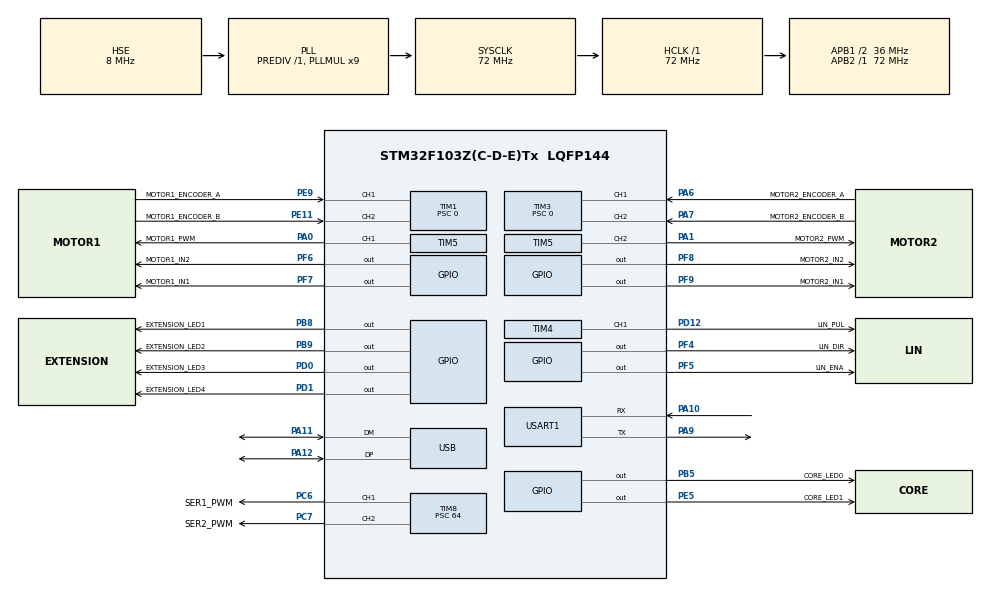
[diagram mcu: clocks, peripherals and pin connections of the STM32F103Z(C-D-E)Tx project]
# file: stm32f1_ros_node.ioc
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Dma.Request0=USART1_RX
Dma.Request1=USART1_TX
Dma.USART1_RX.0.Direction=DMA_PERIPH_TO_MEMORY
Dma.USART1_RX.0.Instance=DMA1_Channel5
Dma.USART1_RX.0.MemDataAlignment=DMA_MDATAALIGN_BYTE
Dma.USART1_RX.0.MemInc=DMA_MINC_ENABLE
Dma.USART1_RX.0.Mode=DMA_CIRCULAR
Dma.USART1_RX.0.PeriphDataAlignment=DMA_PDATAALIGN_BYTE
Dma.USART1_RX.0.PeriphInc=DMA_PINC_DISABLE
Dma.USART1_RX.0.Priority=DMA_PRIORITY_HIGH
Dma.USART1_TX.1.Direction=DMA_MEMORY_TO_PERIPH
Dma.USART1_TX.1.Instance=DMA1_Channel4
Dma.USART1_TX.1.MemDataAlignment=DMA_MDATAALIGN_BYTE
Dma.USART1_TX.1.MemInc=DMA_MINC_ENABLE
Dma.USART1_TX.1.Mode=DMA_NORMAL
Dma.USART1_TX.1.PeriphDataAlignment=DMA_PDATAALIGN_BYTE
Dma.USART1_TX.1.PeriphInc=DMA_PINC_DISABLE
Dma.USART1_TX.1.Priority=DMA_PRIORITY_HIGH
IWDG.Prescaler=IWDG_PRESCALER_128
Mcu.Family=STM32F1
Mcu.Name=STM32F103Z(C-D-E)Tx
Mcu.Package=LQFP144
NVIC.DMA1_Channel4_IRQn=true\:0\:0\:false\:false\:true\:false\:true
NVIC.DMA1_Channel5_IRQn=true\:0\:0\:false\:false\:true\:false\:true
NVIC.PriorityGroup=NVIC_PRIORITYGROUP_4
NVIC.USART1_IRQn=true\:0\:0\:false\:false\:true\:true\:true
NVIC.USB_LP_CAN1_RX0_IRQn=true\:0\:0\:false\:false\:true\:false\:true
OSC_IN.Mode=HSE-External-Oscillator
OSC_IN.Signal=RCC_OSC_IN
OSC_OUT.Mode=HSE-External-Oscillator
OSC_OUT.Signal=RCC_OSC_OUT
PA0-WKUP.GPIO_Label=MOTOR1_PWM
PA0-WKUP.Signal=S_TIM5_CH1
PA1.GPIO_Label=MOTOR2_PWM
PA1.Signal=S_TIM5_CH2
PA10.Mode=Asynchronous
PA10.Signal=USART1_RX
PA11.Mode=Device
PA11.Signal=USB_DM
PA12.Mode=Device
PA12.Signal=USB_DP
PA13.Mode=JTAG_5_pins
PA13.Signal=SYS_JTMS-SWDIO
PA14.Mode=JTAG_5_pins
PA14.Signal=SYS_JTCK-SWCLK
PA15.Mode=JTAG_5_pins
PA15.Signal=SYS_JTDI
PA6.GPIO_Label=MOTOR2_ENCODER_A
PA6.Signal=S_TIM3_CH1
PA7.GPIO_Label=MOTOR2_ENCODER_B
PA7.Signal=S_TIM3_CH2
PA9.Mode=Asynchronous
PA9.Signal=USART1_TX
PB3.Mode=JTAG_5_pins
PB3.Signal=SYS_JTDO-TRACESWO
PB4.Mode=JTAG_5_pins
PB4.Signal=SYS_NJTRST
PB5.GPIO_Label=CORE_LED0
PB5.Signal=GPIO_Output
PB8.GPIO_Label=EXTENSION_LED1
PB8.Signal=GPIO_Output
PB9.GPIO_Label=EXTENSION_LED2
PB9.Signal=GPIO_Output
PC14-OSC32_IN.Mode=LSE-External-Oscillator
PC14-OSC32_IN.Signal=RCC_OSC32_IN
PC15-OSC32_OUT.Mode=LSE-External-Oscillator
PC15-OSC32_OUT.Signal=RCC_OSC32_OUT
PC6.GPIO_Label=SER1_PWM
PC6.Signal=S_TIM8_CH1
PC7.GPIO_Label=SER2_PWM
PC7.Signal=S_TIM8_CH2
PD0.GPIO_Label=EXTENSION_LED3
PD0.Signal=GPIO_Output
PD1.GPIO_Label=EXTENSION_LED4
PD1.Signal=GPIO_Output
PD12.GPIO_Label=LIN_PUL
PD12.Signal=S_TIM4_CH1
PE11.GPIO_Label=MOTOR1_ENCODER_B
PE11.Signal=S_TIM1_CH2
PE5.GPIO_Label=CORE_LED1
PE5.Signal=GPIO_Output
PE9.GPIO_Label=MOTOR1_ENCODER_A
PE9.Signal=S_TIM1_CH1
PF4.GPIO_Label=LIN_DIR
PF4.Signal=GPIO_Output
PF5.GPIO_Label=LIN_ENA
PF5.Signal=GPIO_Output
PF6.GPIO_Label=MOTOR1_IN2
PF6.Signal=GPIO_Output
PF7.GPIO_Label=MOTOR1_IN1
PF7.Signal=GPIO_Output
PF8.GPIO_Label=MOTOR2_IN2
PF8.Signal=GPIO_Output
PF9.GPIO_Label=MOTOR2_IN1
PF9.Signal=GPIO_Output
ProjectManager.HeapSize=0x1000
ProjectManager.StackSize=0x800
ProjectManager.TargetToolchain=MDK-ARM V5.32
RCC.AHBFreq_Value=72000000
RCC.APB1CLKDivider=RCC_HCLK_DIV2
RCC.APB1Freq_Value=36000000
RCC.APB1TimFreq_Value=72000000
RCC.APB2Freq_Value=72000000
RCC.APB2TimFreq_Value=72000000
RCC.HCLKFreq_Value=72000000
RCC.PLLMUL=RCC_PLL_MUL9
RCC.PLLSourceVirtual=RCC_PLLSOURCE_HSE
RCC.SYSCLKFreq_VALUE=72000000
RCC.SYSCLKSource=RCC_SYSCLKSOURCE_PLLCLK
RCC.USBFreq_Value=48000000
RCC.USBPrescaler=RCC_USBCLKSOURCE_PLL_DIV1_5
SH.S_TIM1_CH1.0=TIM1_CH1,Encoder_Interface
SH.S_TIM1_CH2.0=TIM1_CH2,Encoder_Interface
SH.S_TIM3_CH1.0=TIM3_CH1,Encoder_Interface
SH.S_TIM3_CH2.0=TIM3_CH2,Encoder_Interface
SH.S_TIM4_CH1.0=TIM4_CH1,PWM Generation1 CH1
SH.S_TIM5_CH1.0=TIM5_CH1,PWM Generation1 CH1
SH.S_TIM5_CH2.0=TIM5_CH2,PWM Generation2 CH2
SH.S_TIM8_CH1.0=TIM8_CH1,PWM Generation1 CH1
SH.S_TIM8_CH2.0=TIM8_CH2,PWM Generation2 CH2
TIM1.CounterMode=TIM_COUNTERMODE_UP
TIM1.EncoderMode=TIM_ENCODERMODE_TI12
TIM1.Period=65535
TIM1.Prescaler=0
TIM3.EncoderMode=TIM_ENCODERMODE_TI12
TIM3.Period=65535
TIM3.Prescaler=0
TIM4.Channel-PWM\ Generation1\ CH1=TIM_CHANNEL_1
TIM4.Period=1000
TIM4.Prescaler=64
TIM5.Channel-PWM\ Generation1\ CH1=TIM_CHANNEL_1
TIM5.Channel-PWM\ Generation2\ CH2=TIM_CHANNEL_2
TIM5.Period=3600
TIM5.Prescaler=20
TIM8.Channel-PWM\ Generation1\ CH1=TIM_CHANNEL_1
TIM8.Channel-PWM\ Generation2\ CH2=TIM_CHANNEL_2
TIM8.Period=20000
TIM8.Prescaler=64
USART1.VirtualMode=VM_ASYNC
USB_DEVICE.CLASS_NAME_FS=CDC
USB_DEVICE.VirtualMode=Cdc
USB_DEVICE.VirtualModeFS=Cdc_FS
VP_IWDG_VS_IWDG.Mode=IWDG_Activate
VP_TIM4_VS_ClockSourceINT.Mode=Internal
VP_TIM5_VS_ClockSourceINT.Mode=Internal
VP_TIM8_VS_ClockSourceINT.Mode=Internal
VP_USB_DEVICE_VS_USB_DEVICE_CDC_FS.Mode=CDC_FS
board=custom

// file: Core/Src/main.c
/* USER CODE BEGIN Header */
/**
  ******************************************************************************
  * @file           : main.c
  * @brief          : Main program body
  ******************************************************************************
  * @attention
  *
  * <h2><center>&copy; Copyright (c) 2021 STMicroelectronics.
  * All rights reserved.</center></h2>
  *
  * This software component is licensed by ST under BSD 3-Clause license,
  * the "License"; You may not use this file except in compliance with the
  * License. You may obtain a copy of the License at:
  *                        opensource.org/licenses/BSD-3-Clause
  *
  ******************************************************************************
  */
/* USER CODE END Header */
#include "main.h"
#include "usb_device.h"

/* USER CODE BEGIN Includes */
#include "usbd_cdc_if.h"
#include "ros_main.h"
/* USER CODE END Includes */

IWDG_HandleTypeDef hiwdg;

TIM_HandleTypeDef htim1;
TIM_HandleTypeDef htim3;
TIM_HandleTypeDef htim4;
TIM_HandleTypeDef htim5;
TIM_HandleTypeDef htim8;

UART_HandleTypeDef huart1;
DMA_HandleTypeDef hdma_usart1_rx;
DMA_HandleTypeDef hdma_usart1_tx;

void SystemClock_Config(void);
static void MX_GPIO_Init(void);
static void MX_DMA_Init(void);
static void MX_USART1_UART_Init(void);
static void MX_TIM1_Init(void);
static void MX_TIM3_Init(void);
static void MX_TIM4_Init(void);
static void MX_TIM5_Init(void);
static void MX_IWDG_Init(void);
static void MX_TIM8_Init(void);

int main(void)
{

  /* MCU Configuration--------------------------------------------------------*/

  /* Reset of all peripherals, Initializes the Flash interface and the Systick. */
  HAL_Init();

  /* Configure the system clock */
  SystemClock_Config();

  /* Initialize all configured peripherals */
  MX_GPIO_Init();
  MX_DMA_Init();
  MX_USART1_UART_Init();
  MX_TIM1_Init();
  MX_TIM3_Init();
  MX_TIM4_Init();
  MX_TIM5_Init();
  MX_USB_DEVICE_Init();
  MX_IWDG_Init();
  MX_TIM8_Init();
  /* USER CODE BEGIN 2 */
	setup();
  /* USER CODE END 2 */

  /* Infinite loop */
  /* USER CODE BEGIN WHILE */
  while (1)
  {
		loop();
    /* USER CODE END WHILE */

  }
}

void SystemClock_Config(void)
{
  RCC_OscInitTypeDef RCC_OscInitStruct = {0};
  RCC_ClkInitTypeDef RCC_ClkInitStruct = {0};
  RCC_PeriphCLKInitTypeDef PeriphClkInit = {0};

  /** Initializes the RCC Oscillators according to the specified parameters
  * in the RCC_OscInitTypeDef structure.
  */
  RCC_OscInitStruct.OscillatorType = RCC_OSCILLATORTYPE_LSI|RCC_OSCILLATORTYPE_HSE;
  RCC_OscInitStruct.HSEState = RCC_HSE_ON;
  RCC_OscInitStruct.HSEPredivValue = RCC_HSE_PREDIV_DIV1;
  RCC_OscInitStruct.HSIState = RCC_HSI_ON;
  RCC_OscInitStruct.LSIState = RCC_LSI_ON;
  RCC_OscInitStruct.PLL.PLLState = RCC_PLL_ON;
  RCC_OscInitStruct.PLL.PLLSource = RCC_PLLSOURCE_HSE;
  RCC_OscInitStruct.PLL.PLLMUL = RCC_PLL_MUL9;
  if (HAL_RCC_OscConfig(&RCC_OscInitStruct) != HAL_OK)
  {
    Error_Handler();
  }
  /** Initializes the CPU, AHB and APB buses clocks
  */
  RCC_ClkInitStruct.ClockType = RCC_CLOCKTYPE_HCLK|RCC_CLOCKTYPE_SYSCLK
                              |RCC_CLOCKTYPE_PCLK1|RCC_CLOCKTYPE_PCLK2;
  RCC_ClkInitStruct.SYSCLKSource = RCC_SYSCLKSOURCE_PLLCLK;
  RCC_ClkInitStruct.AHBCLKDivider = RCC_SYSCLK_DIV1;
  RCC_ClkInitStruct.APB1CLKDivider = RCC_HCLK_DIV2;
  RCC_ClkInitStruct.APB2CLKDivider = RCC_HCLK_DIV1;

  if (HAL_RCC_ClockConfig(&RCC_ClkInitStruct, FLASH_LATENCY_2) != HAL_OK)
  {
    Error_Handler();
  }
  PeriphClkInit.PeriphClockSelection = RCC_PERIPHCLK_USB;
  PeriphClkInit.UsbClockSelection = RCC_USBCLKSOURCE_PLL_DIV1_5;
  if (HAL_RCCEx_PeriphCLKConfig(&PeriphClkInit) != HAL_OK)
  {
    Error_Handler();
  }
}

static void MX_IWDG_Init(void)
{

  hiwdg.Instance = IWDG;
  hiwdg.Init.Prescaler = IWDG_PRESCALER_128;
  hiwdg.Init.Reload = 4095;
  if (HAL_IWDG_Init(&hiwdg) != HAL_OK)
  {
    Error_Handler();
  }

}

static void MX_TIM1_Init(void)
{

  TIM_Encoder_InitTypeDef sConfig = {0};
  TIM_MasterConfigTypeDef sMasterConfig = {0};

  htim1.Instance = TIM1;
  htim1.Init.Prescaler = 0;
  htim1.Init.CounterMode = TIM_COUNTERMODE_DOWN;
  htim1.Init.Period = 65535;
  htim1.Init.ClockDivision = TIM_CLOCKDIVISION_DIV1;
  htim1.Init.RepetitionCounter = 0;
  htim1.Init.AutoReloadPreload = TIM_AUTORELOAD_PRELOAD_DISABLE;
  sConfig.EncoderMode = TIM_ENCODERMODE_TI12;
  sConfig.IC1Polarity = TIM_ICPOLARITY_RISING;
  sConfig.IC1Selection = TIM_ICSELECTION_DIRECTTI;
  sConfig.IC1Prescaler = TIM_ICPSC_DIV1;
  sConfig.IC1Filter = 0;
  sConfig.IC2Polarity = TIM_ICPOLARITY_RISING;
  sConfig.IC2Selection = TIM_ICSELECTION_DIRECTTI;
  sConfig.IC2Prescaler = TIM_ICPSC_DIV1;
  sConfig.IC2Filter = 0;
  if (HAL_TIM_Encoder_Init(&htim1, &sConfig) != HAL_OK)
  {
    Error_Handler();
  }
  sMasterConfig.MasterOutputTrigger = TIM_TRGO_RESET;
  sMasterConfig.MasterSlaveMode = TIM_MASTERSLAVEMODE_DISABLE;
  if (HAL_TIMEx_MasterConfigSynchronization(&htim1, &sMasterConfig) != HAL_OK)
  {
    Error_Handler();
  }

}

static void MX_TIM3_Init(void)
{

  TIM_Encoder_InitTypeDef sConfig = {0};
  TIM_MasterConfigTypeDef sMasterConfig = {0};

  htim3.Instance = TIM3;
  htim3.Init.Prescaler = 0;
  htim3.Init.CounterMode = TIM_COUNTERMODE_UP;
  htim3.Init.Period = 65535;
  htim3.Init.ClockDivision = TIM_CLOCKDIVISION_DIV1;
  htim3.Init.AutoReloadPreload = TIM_AUTORELOAD_PRELOAD_DISABLE;
  sConfig.EncoderMode = TIM_ENCODERMODE_TI12;
  sConfig.IC1Polarity = TIM_ICPOLARITY_RISING;
  sConfig.IC1Selection = TIM_ICSELECTION_DIRECTTI;
  sConfig.IC1Prescaler = TIM_ICPSC_DIV1;
  sConfig.IC1Filter = 0;
  sConfig.IC2Polarity = TIM_ICPOLARITY_RISING;
  sConfig.IC2Selection = TIM_ICSELECTION_DIRECTTI;
  sConfig.IC2Prescaler = TIM_ICPSC_DIV1;
  sConfig.IC2Filter = 0;
  if (HAL_TIM_Encoder_Init(&htim3, &sConfig) != HAL_OK)
  {
    Error_Handler();
  }
  sMasterConfig.MasterOutputTrigger = TIM_TRGO_RESET;
  sMasterConfig.MasterSlaveMode = TIM_MASTERSLAVEMODE_DISABLE;
  if (HAL_TIMEx_MasterConfigSynchronization(&htim3, &sMasterConfig) != HAL_OK)
  {
    Error_Handler();
  }

}

static void MX_TIM4_Init(void)
{

  TIM_ClockConfigTypeDef sClockSourceConfig = {0};
  TIM_MasterConfigTypeDef sMasterConfig = {0};
  TIM_OC_InitTypeDef sConfigOC = {0};

  htim4.Instance = TIM4;
  htim4.Init.Prescaler = 64;
  htim4.Init.CounterMode = TIM_COUNTERMODE_UP;
  htim4.Init.Period = 1000;
  htim4.Init.ClockDivision = TIM_CLOCKDIVISION_DIV1;
  htim4.Init.AutoReloadPreload = TIM_AUTORELOAD_PRELOAD_DISABLE;
  if (HAL_TIM_Base_Init(&htim4) != HAL_OK)
  {
    Error_Handler();
  }
  sClockSourceConfig.ClockSource = TIM_CLOCKSOURCE_INTERNAL;
  if (HAL_TIM_ConfigClockSource(&htim4, &sClockSourceConfig) != HAL_OK)
  {
    Error_Handler();
  }
  if (HAL_TIM_PWM_Init(&htim4) != HAL_OK)
  {
    Error_Handler();
  }
  sMasterConfig.MasterOutputTrigger = TIM_TRGO_RESET;
  sMasterConfig.MasterSlaveMode = TIM_MASTERSLAVEMODE_DISABLE;
  if (HAL_TIMEx_MasterConfigSynchronization(&htim4, &sMasterConfig) != HAL_OK)
  {
    Error_Handler();
  }
  sConfigOC.OCMode = TIM_OCMODE_PWM1;
  sConfigOC.Pulse = 0;
  sConfigOC.OCPolarity = TIM_OCPOLARITY_HIGH;
  sConfigOC.OCFastMode = TIM_OCFAST_DISABLE;
  if (HAL_TIM_PWM_ConfigChannel(&htim4, &sConfigOC, TIM_CHANNEL_1) != HAL_OK)
  {
    Error_Handler();
  }
  HAL_TIM_MspPostInit(&htim4);

}

static void MX_TIM5_Init(void)
{

  TIM_ClockConfigTypeDef sClockSourceConfig = {0};
  TIM_MasterConfigTypeDef sMasterConfig = {0};
  TIM_OC_InitTypeDef sConfigOC = {0};

  htim5.Instance = TIM5;
  htim5.Init.Prescaler = 20;
  htim5.Init.CounterMode = TIM_COUNTERMODE_UP;
  htim5.Init.Period = 3600;
  htim5.Init.ClockDivision = TIM_CLOCKDIVISION_DIV1;
  htim5.Init.AutoReloadPreload = TIM_AUTORELOAD_PRELOAD_DISABLE;
  if (HAL_TIM_Base_Init(&htim5) != HAL_OK)
  {
    Error_Handler();
  }
  sClockSourceConfig.ClockSource = TIM_CLOCKSOURCE_INTERNAL;
  if (HAL_TIM_ConfigClockSource(&htim5, &sClockSourceConfig) != HAL_OK)
  {
    Error_Handler();
  }
  if (HAL_TIM_PWM_Init(&htim5) != HAL_OK)
  {
    Error_Handler();
  }
  sMasterConfig.MasterOutputTrigger = TIM_TRGO_RESET;
  sMasterConfig.MasterSlaveMode = TIM_MASTERSLAVEMODE_DISABLE;
  if (HAL_TIMEx_MasterConfigSynchronization(&htim5, &sMasterConfig) != HAL_OK)
  {
    Error_Handler();
  }
  sConfigOC.OCMode = TIM_OCMODE_PWM1;
  sConfigOC.Pulse = 0;
  sConfigOC.OCPolarity = TIM_OCPOLARITY_HIGH;
  sConfigOC.OCFastMode = TIM_OCFAST_DISABLE;
  if (HAL_TIM_PWM_ConfigChannel(&htim5, &sConfigOC, TIM_CHANNEL_1) != HAL_OK)
  {
    Error_Handler();
  }
  if (HAL_TIM_PWM_ConfigChannel(&htim5, &sConfigOC, TIM_CHANNEL_2) != HAL_OK)
  {
    Error_Handler();
  }
  HAL_TIM_MspPostInit(&htim5);

}

static void MX_TIM8_Init(void)
{

  TIM_ClockConfigTypeDef sClockSourceConfig = {0};
  TIM_MasterConfigTypeDef sMasterConfig = {0};
  TIM_OC_InitTypeDef sConfigOC = {0};
  TIM_BreakDeadTimeConfigTypeDef sBreakDeadTimeConfig = {0};

  htim8.Instance = TIM8;
  htim8.Init.Prescaler = 64;
  htim8.Init.CounterMode = TIM_COUNTERMODE_UP;
  htim8.Init.Period = 20000;
  htim8.Init.ClockDivision = TIM_CLOCKDIVISION_DIV1;
  htim8.Init.RepetitionCounter = 0;
  htim8.Init.AutoReloadPreload = TIM_AUTORELOAD_PRELOAD_DISABLE;
  if (HAL_TIM_Base_Init(&htim8) != HAL_OK)
  {
    Error_Handler();
  }
  sClockSourceConfig.ClockSource = TIM_CLOCKSOURCE_INTERNAL;
  if (HAL_TIM_ConfigClockSource(&htim8, &sClockSourceConfig) != HAL_OK)
  {
    Error_Handler();
  }
  if (HAL_TIM_PWM_Init(&htim8) != HAL_OK)
  {
    Error_Handler();
  }
  sMasterConfig.MasterOutputTrigger = TIM_TRGO_RESET;
  sMasterConfig.MasterSlaveMode = TIM_MASTERSLAVEMODE_DISABLE;
  if (HAL_TIMEx_MasterConfigSynchronization(&htim8, &sMasterConfig) != HAL_OK)
  {
    Error_Handler();
  }
  sConfigOC.OCMode = TIM_OCMODE_PWM1;
  sConfigOC.Pulse = 0;
  sConfigOC.OCPolarity = TIM_OCPOLARITY_HIGH;
  sConfigOC.OCNPolarity = TIM_OCNPOLARITY_HIGH;
  sConfigOC.OCFastMode = TIM_OCFAST_DISABLE;
  sConfigOC.OCIdleState = TIM_OCIDLESTATE_RESET;
  sConfigOC.OCNIdleState = TIM_OCNIDLESTATE_RESET;
  if (HAL_TIM_PWM_ConfigChannel(&htim8, &sConfigOC, TIM_CHANNEL_1) != HAL_OK)
  {
    Error_Handler();
  }
  if (HAL_TIM_PWM_ConfigChannel(&htim8, &sConfigOC, TIM_CHANNEL_2) != HAL_OK)
  {
    Error_Handler();
  }
  sBreakDeadTimeConfig.OffStateRunMode = TIM_OSSR_DISABLE;
  sBreakDeadTimeConfig.OffStateIDLEMode = TIM_OSSI_DISABLE;
  sBreakDeadTimeConfig.LockLevel = TIM_LOCKLEVEL_OFF;
  sBreakDeadTimeConfig.DeadTime = 0;
  sBreakDeadTimeConfig.BreakState = TIM_BREAK_DISABLE;
  sBreakDeadTimeConfig.BreakPolarity = TIM_BREAKPOLARITY_HIGH;
  sBreakDeadTimeConfig.AutomaticOutput = TIM_AUTOMATICOUTPUT_DISABLE;
  if (HAL_TIMEx_ConfigBreakDeadTime(&htim8, &sBreakDeadTimeConfig) != HAL_OK)
  {
    Error_Handler();
  }
  HAL_TIM_MspPostInit(&htim8);

}

static void MX_USART1_UART_Init(void)
{

  huart1.Instance = USART1;
  huart1.Init.BaudRate = 115200;
  huart1.Init.WordLength = UART_WORDLENGTH_8B;
  huart1.Init.StopBits = UART_STOPBITS_1;
  huart1.Init.Parity = UART_PARITY_NONE;
  huart1.Init.Mode = UART_MODE_TX_RX;
  huart1.Init.HwFlowCtl = UART_HWCONTROL_NONE;
  huart1.Init.OverSampling = UART_OVERSAMPLING_16;
  if (HAL_UART_Init(&huart1) != HAL_OK)
  {
    Error_Handler();
  }

}

static void MX_DMA_Init(void)
{

  /* DMA controller clock enable */
  __HAL_RCC_DMA1_CLK_ENABLE();

  /* DMA interrupt init */
  /* DMA1_Channel4_IRQn interrupt configuration */
  HAL_NVIC_SetPriority(DMA1_Channel4_IRQn, 0, 0);
  HAL_NVIC_EnableIRQ(DMA1_Channel4_IRQn);
  /* DMA1_Channel5_IRQn interrupt configuration */
  HAL_NVIC_SetPriority(DMA1_Channel5_IRQn, 0, 0);
  HAL_NVIC_EnableIRQ(DMA1_Channel5_IRQn);

}

static void MX_GPIO_Init(void)
{
  GPIO_InitTypeDef GPIO_InitStruct = {0};

  /* GPIO Ports Clock Enable */
  __HAL_RCC_GPIOE_CLK_ENABLE();
  __HAL_RCC_GPIOC_CLK_ENABLE();
  __HAL_RCC_GPIOF_CLK_ENABLE();
  __HAL_RCC_GPIOA_CLK_ENABLE();
  __HAL_RCC_GPIOD_CLK_ENABLE();
  __HAL_RCC_GPIOB_CLK_ENABLE();

  /*Configure GPIO pin Output Level */
  HAL_GPIO_WritePin(CORE_LED1_GPIO_Port, CORE_LED1_Pin, GPIO_PIN_RESET);

  /*Configure GPIO pin Output Level */
  HAL_GPIO_WritePin(GPIOF, LIN_DIR_Pin|LIN_ENA_Pin|MOTOR1_IN2_Pin|MOTOR1_IN1_Pin
                          |MOTOR2_IN2_Pin|MOTOR2_IN1_Pin, GPIO_PIN_RESET);

  /*Configure GPIO pin Output Level */
  HAL_GPIO_WritePin(GPIOD, EXTENSION_LED3_Pin|EXTENSION_LED4_Pin, GPIO_PIN_RESET);

  /*Configure GPIO pin Output Level */
  HAL_GPIO_WritePin(GPIOB, CORE_LED0_Pin|EXTENSION_LED1_Pin|EXTENSION_LED2_Pin, GPIO_PIN_RESET);

  /*Configure GPIO pin : CORE_LED1_Pin */
  GPIO_InitStruct.Pin = CORE_LED1_Pin;
  GPIO_InitStruct.Mode = GPIO_MODE_OUTPUT_PP;
  GPIO_InitStruct.Pull = GPIO_NOPULL;
  GPIO_InitStruct.Speed = GPIO_SPEED_FREQ_LOW;
  HAL_GPIO_Init(CORE_LED1_GPIO_Port, &GPIO_InitStruct);

  /*Configure GPIO pins : LIN_DIR_Pin LIN_ENA_Pin MOTOR1_IN2_Pin MOTOR1_IN1_Pin
                           MOTOR2_IN2_Pin MOTOR2_IN1_Pin */
  GPIO_InitStruct.Pin = LIN_DIR_Pin|LIN_ENA_Pin|MOTOR1_IN2_Pin|MOTOR1_IN1_Pin
                          |MOTOR2_IN2_Pin|MOTOR2_IN1_Pin;
  GPIO_InitStruct.Mode = GPIO_MODE_OUTPUT_PP;
  GPIO_InitStruct.Pull = GPIO_NOPULL;
  GPIO_InitStruct.Speed = GPIO_SPEED_FREQ_LOW;
  HAL_GPIO_Init(GPIOF, &GPIO_InitStruct);

  /*Configure GPIO pins : EXTENSION_LED3_Pin EXTENSION_LED4_Pin */
  GPIO_InitStruct.Pin = EXTENSION_LED3_Pin|EXTENSION_LED4_Pin;
  GPIO_InitStruct.Mode = GPIO_MODE_OUTPUT_PP;
  GPIO_InitStruct.Pull = GPIO_NOPULL;
  GPIO_InitStruct.Speed = GPIO_SPEED_FREQ_LOW;
  HAL_GPIO_Init(GPIOD, &GPIO_InitStruct);

  /*Configure GPIO pins : CORE_LED0_Pin EXTENSION_LED1_Pin EXTENSION_LED2_Pin */
  GPIO_InitStruct.Pin = CORE_LED0_Pin|EXTENSION_LED1_Pin|EXTENSION_LED2_Pin;
  GPIO_InitStruct.Mode = GPIO_MODE_OUTPUT_PP;
  GPIO_InitStruct.Pull = GPIO_NOPULL;
  GPIO_InitStruct.Speed = GPIO_SPEED_FREQ_LOW;
  HAL_GPIO_Init(GPIOB, &GPIO_InitStruct);

}

void Error_Handler(void)
{
  __disable_irq();
  while (1)
  {
  }
}

/************************ (C) COPYRIGHT STMicroelectronics *****END OF FILE****/
